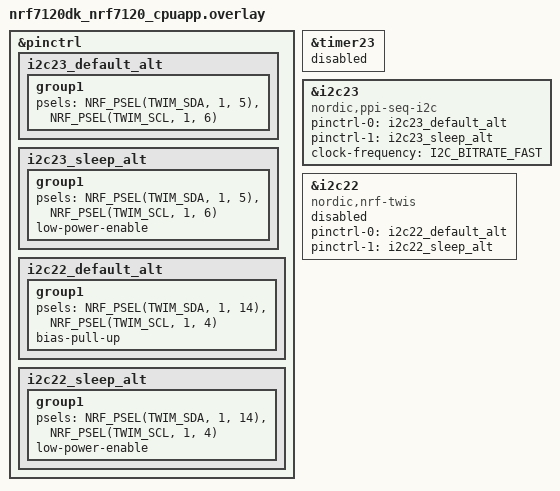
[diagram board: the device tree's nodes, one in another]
/*
 * Copyright (c) 2026 Nordic Semiconductor ASA
 *
 * SPDX-License-Identifier: LicenseRef-Nordic-5-Clause
 */

/* Test requires loopbacks:
 * - between P1.05 and P1.14
 * - between P1.06 and P1.04
 */

&pinctrl {
	i2c23_default_alt: i2c23_default_alt {
		group1 {
			psels = <NRF_PSEL(TWIM_SDA, 1, 5)>,
				<NRF_PSEL(TWIM_SCL, 1, 6)>;
		};
	};

	i2c23_sleep_alt: i2c23_sleep_alt {
		group1 {
			psels = <NRF_PSEL(TWIM_SDA, 1, 5)>,
				<NRF_PSEL(TWIM_SCL, 1, 6)>;
			low-power-enable;
		};
	};

	i2c22_default_alt: i2c22_default_alt {
		group1 {
			/* Temporary workaround as it is currently not possible
			 * to configure pins for TWIS with pinctrl.
			 */
			psels = <NRF_PSEL(TWIM_SDA, 1, 14)>,
				<NRF_PSEL(TWIM_SCL, 1, 4)>;
			bias-pull-up;
		};
	};

	i2c22_sleep_alt: i2c22_sleep_alt {
		group1 {
			psels = <NRF_PSEL(TWIM_SDA, 1, 14)>,
				<NRF_PSEL(TWIM_SCL, 1, 4)>;
			low-power-enable;
		};
	};
};

test_timer: &timer23 {
	status = "reserved";
};

dut: &i2c23 {
	compatible = "nordic,ppi-seq-i2c";
	status = "okay";
	pinctrl-0 = <&i2c23_default_alt>;
	pinctrl-1 = <&i2c23_sleep_alt>;
	pinctrl-names = "default", "sleep";
	clock-frequency = <I2C_BITRATE_FAST>;
};

tester: &i2c22 {
	compatible = "nordic,nrf-twis";
	status = "reserved";
	pinctrl-0 = <&i2c22_default_alt>;
	pinctrl-1 = <&i2c22_sleep_alt>;
	pinctrl-names = "default", "sleep";
};
